# GTC_GTC_CFG0_00A80000h register map
Vendor: Texas Instruments
Peripheral module from a debugger description file (folder am62L).
Registers are 32-bit, read-only, reset 0x61800209 unless marked. A register's access mark holds for its fields unless they carry their own. Offsets are as the file gives them; lines under a group give offsets from that group; [hi:lo] are bit positions; {n}, {i} and the like mark numbered series; 'fields as' and 'values as' point back to an identical list; <NAME> marks a mode.

## GTC_CFG0
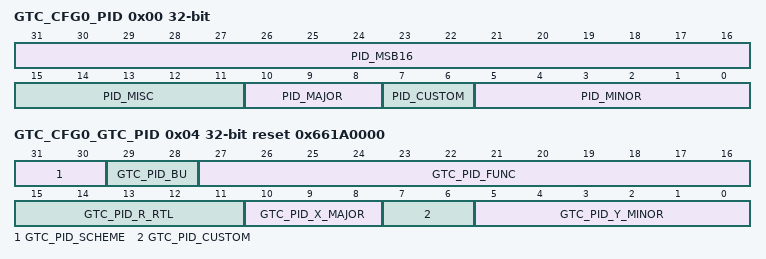
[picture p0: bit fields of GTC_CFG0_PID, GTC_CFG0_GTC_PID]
0x00 GTC_CFG0_PID
  [31:16] PID_MSB16 — Reset Source: mod_g_rst_n
  [15:11] PID_MISC — Reset Source: mod_g_rst_n
  [10:8] PID_MAJOR — Reset Source: mod_g_rst_n
  [7:6] PID_CUSTOM — Reset Source: mod_g_rst_n
  [5:0] PID_MINOR — Reset Source: mod_g_rst_n
0x04 GTC_CFG0_GTC_PID reset 0x661A0000
  [31:30] GTC_PID_SCHEME — PID follows new scheme Reset Source: mod_por_rst_n
  [29:28] GTC_PID_BU — Business unit - Processors Reset Source: mod_por_rst_n
  [27:16] GTC_PID_FUNC — Module functional identifier - GTC module Reset Source: mod_por_rst_n
  [15:11] GTC_PID_R_RTL — RTL revision number - actual value determined by RTL Reset Source: mod_por_rst_n
  [10:8] GTC_PID_X_MAJOR — Major revision number - actual value determined by RTL Reset Source: mod_por_rst_n
  [7:6] GTC_PID_CUSTOM — Custom revision number - actual value determined by RTL Reset Source: mod_por_rst_n
  [5:0] GTC_PID_Y_MINOR — Minor revision number - actual value determined by RTL Reset Source: mod_por_rst_n
0x08 GTC_CFG0_PUSHEVT rw reset 0x0
  [5:0] PUSHEVT_EXPBIT_SEL — Selects which bit [63:0] of the System Counter value is exported on the push_evt output. This field controls the 64:1 mux that drives the push_evt output. Reset Source: mod_por_rst_n
